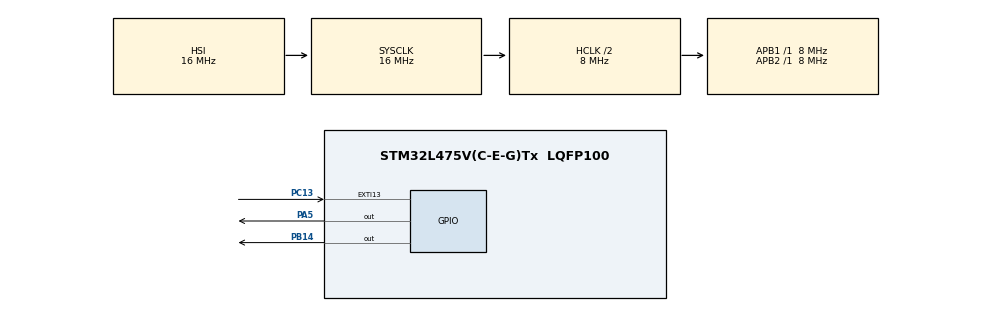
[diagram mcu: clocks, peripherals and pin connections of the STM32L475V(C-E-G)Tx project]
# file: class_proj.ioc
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Mcu.Family=STM32L4
RCC.MSI_VALUE=4000000
RCC.CortexFreq_Value=8000000
PC13.Signal=GPXTI13
RCC.SYSCLKSource=RCC_SYSCLKSOURCE_HSI
ProjectManager.StackSize=0x400
ProjectManager.TargetToolchain=EWARM V8.32
RCC.HCLKFreq_Value=8000000
RCC.APB2TimFreq_Value=8000000
RCC.USBFreq_Value=48000000
RCC.LSE_VALUE=32768
RCC.AHBFreq_Value=8000000
NVIC.EXTI15_10_IRQn=true\:0\:0\:false\:false\:true\:true\:true
PB14.Signal=GPIO_Output
PA5.Signal=GPIO_Output
RCC.HSE_VALUE=8000000
board=B-L475E-IOT01A1
RCC.VCOOutputFreq_Value=160000000
RCC.APB2Freq_Value=8000000
RCC.ADCFreq_Value=48000000
RCC.AHBCLKDivider=RCC_SYSCLK_DIV2
Mcu.Name=STM32L475V(C-E-G)Tx
RCC.SYSCLKFreq_VALUE=16000000
Mcu.Package=LQFP100
PC13.GPIO_ModeDefaultEXTI=GPIO_MODE_IT_FALLING
ProjectManager.HeapSize=0x200
RCC.HSI_VALUE=16000000
NVIC.PriorityGroup=NVIC_PRIORITYGROUP_4
RCC.PLLN=40
RCC.APB1TimFreq_Value=8000000
RCC.APB1Freq_Value=8000000
RCC.PLLSAI1N=24

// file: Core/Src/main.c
/* USER CODE BEGIN Header */
/**
  ******************************************************************************
  * @file           : main.c
  * @brief          : Main program body
  ******************************************************************************
  * @attention
  *
  * <h2><center>&copy; Copyright (c) 2020 STMicroelectronics.
  * All rights reserved.</center></h2>
  *
  * This software component is licensed by ST under BSD 3-Clause license,
  * the "License"; You may not use this file except in compliance with the
  * License. You may obtain a copy of the License at:
  *                        opensource.org/licenses/BSD-3-Clause
  *
  ******************************************************************************
  */
/* USER CODE END Header */
#include "main.h"

/* USER CODE BEGIN Includes */
#include "led_states.h"
/* USER CODE END Includes */

/* USER CODE BEGIN PV */
extern volatile uint32_t uwTick;
//extern enum LED_STATES led_state;
/* USER CODE END PV */

void SystemClock_Config(void);
static void MX_GPIO_Init(void);

int main(void)
{
  /* USER CODE BEGIN 1 */
    uint16_t led_delay = 0;
  /* USER CODE END 1 */

  /* MCU Configuration--------------------------------------------------------*/

  /* Reset of all peripherals, Initializes the Flash interface and the Systick. */
  HAL_Init();

  /* Configure the system clock */
  SystemClock_Config();

  /* Initialize all configured peripherals */
  MX_GPIO_Init();

  /* Infinite loop */
  /* USER CODE BEGIN WHILE */
  while (1)
  {
      /*if(uwTick >= 500) {
          HAL_GPIO_TogglePin(GPIOB, GPIO_PIN_14);
          uwTick = 0;
      }*/
  switch (led_state) {
      case LED_OFF:
          HAL_GPIO_WritePin(GPIOB, GPIO_PIN_14, GPIO_PIN_RESET);
          break;
      case LED_ON:
          HAL_GPIO_WritePin(GPIOB, GPIO_PIN_14, GPIO_PIN_SET);
          break;
      case LED_BLINK_SLOW:
          led_delay = 1000;
          break;
      case LED_BLINK_FAST:
          led_delay = 250;
          break;
      case LED_DIM_SLOW:

          break;
      case LED_DIM_FAST:

          break;

  }

  if (((led_state == LED_BLINK_SLOW) || (led_state == LED_BLINK_FAST)) && (uwTick >= led_delay)) {
      HAL_GPIO_TogglePin(GPIOB, GPIO_PIN_14);
      uwTick = 0;
  }
    /* USER CODE END WHILE */

  }
}

void SystemClock_Config(void)
{
  RCC_OscInitTypeDef RCC_OscInitStruct = {0};
  RCC_ClkInitTypeDef RCC_ClkInitStruct = {0};

  /** Initializes the RCC Oscillators according to the specified parameters
  * in the RCC_OscInitTypeDef structure.
  */
  RCC_OscInitStruct.OscillatorType = RCC_OSCILLATORTYPE_HSI;
  RCC_OscInitStruct.HSIState = RCC_HSI_ON;
  RCC_OscInitStruct.HSICalibrationValue = RCC_HSICALIBRATION_DEFAULT;
  RCC_OscInitStruct.PLL.PLLState = RCC_PLL_NONE;
  if (HAL_RCC_OscConfig(&RCC_OscInitStruct) != HAL_OK)
  {
    Error_Handler();
  }
  /** Initializes the CPU, AHB and APB buses clocks
  */
  RCC_ClkInitStruct.ClockType = RCC_CLOCKTYPE_HCLK|RCC_CLOCKTYPE_SYSCLK
                              |RCC_CLOCKTYPE_PCLK1|RCC_CLOCKTYPE_PCLK2;
  RCC_ClkInitStruct.SYSCLKSource = RCC_SYSCLKSOURCE_HSI;
  RCC_ClkInitStruct.AHBCLKDivider = RCC_SYSCLK_DIV2;
  RCC_ClkInitStruct.APB1CLKDivider = RCC_HCLK_DIV1;
  RCC_ClkInitStruct.APB2CLKDivider = RCC_HCLK_DIV1;

  if (HAL_RCC_ClockConfig(&RCC_ClkInitStruct, FLASH_LATENCY_0) != HAL_OK)
  {
    Error_Handler();
  }
  /** Configure the main internal regulator output voltage
  */
  if (HAL_PWREx_ControlVoltageScaling(PWR_REGULATOR_VOLTAGE_SCALE1) != HAL_OK)
  {
    Error_Handler();
  }
}

static void MX_GPIO_Init(void)
{
  GPIO_InitTypeDef GPIO_InitStruct = {0};

  /* GPIO Ports Clock Enable */
  __HAL_RCC_GPIOC_CLK_ENABLE();
  __HAL_RCC_GPIOA_CLK_ENABLE();
  __HAL_RCC_GPIOB_CLK_ENABLE();

  /*Configure GPIO pin Output Level */
  HAL_GPIO_WritePin(GPIOA, GPIO_PIN_5, GPIO_PIN_RESET);

  /*Configure GPIO pin Output Level */
  HAL_GPIO_WritePin(GPIOB, GPIO_PIN_14, GPIO_PIN_RESET);

  /*Configure GPIO pin : PC13 */
  GPIO_InitStruct.Pin = GPIO_PIN_13;
  GPIO_InitStruct.Mode = GPIO_MODE_IT_FALLING;
  GPIO_InitStruct.Pull = GPIO_NOPULL;
  HAL_GPIO_Init(GPIOC, &GPIO_InitStruct);

  /*Configure GPIO pin : PA5 */
  GPIO_InitStruct.Pin = GPIO_PIN_5;
  GPIO_InitStruct.Mode = GPIO_MODE_OUTPUT_PP;
  GPIO_InitStruct.Pull = GPIO_NOPULL;
  GPIO_InitStruct.Speed = GPIO_SPEED_FREQ_LOW;
  HAL_GPIO_Init(GPIOA, &GPIO_InitStruct);

  /*Configure GPIO pin : PB14 */
  GPIO_InitStruct.Pin = GPIO_PIN_14;
  GPIO_InitStruct.Mode = GPIO_MODE_OUTPUT_PP;
  GPIO_InitStruct.Pull = GPIO_NOPULL;
  GPIO_InitStruct.Speed = GPIO_SPEED_FREQ_LOW;
  HAL_GPIO_Init(GPIOB, &GPIO_InitStruct);

  /* EXTI interrupt init*/
  HAL_NVIC_SetPriority(EXTI15_10_IRQn, 0, 0);
  HAL_NVIC_EnableIRQ(EXTI15_10_IRQn);

}

void Error_Handler(void)
{
}

/************************ (C) COPYRIGHT STMicroelectronics *****END OF FILE****/
